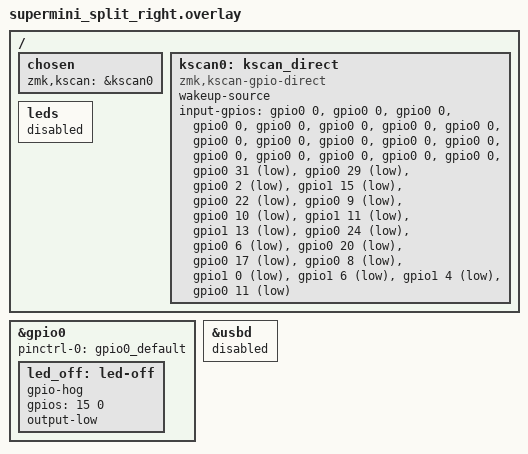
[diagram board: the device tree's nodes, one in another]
/*
 * Right half overlay — Super mini nrf52840
 *
 * This PCB is reversible: the right half is the same board flipped 180°.
 * The columns are therefore mirrored relative to the left overlay.
 * Each row's GPIO list runs innermost (toward centre) → outermost.
 *
 * Corrected column order (firmware pos → physical key → central pos):
 *   Key  0  P0.31  D21  (Y)    Key  5  P0.09  D1   (H)    Key 10  P0.06  D6   (N)
 *   Key  1  P0.29  D20  (U)    Key  6  P0.10  D10  (J)    Key 11  P0.20  D5   (M)
 *   Key  2  P0.02  D19  (I)    Key  7  P1.11  D16  (K)    Key 12  P0.17  D4   (,)
 *   Key  3  P1.15  D18  (O)    Key  8  P1.13  D14  (L)    Key 13  P0.08  D3   (.)
 *   Key  4  P0.22  D7   (P)    Key  9  P0.24  D15  (ö)    Key 14  P1.00  D2   (DEL)
 *   Key 15  P1.06  D0   (right thumb inner / RET)
 *   Key 16  P1.04  D8   (right thumb mid / SPACE)
 *   Key 17  P0.11  D9   (right thumb outer / BSPC)
 *
 * Positions 0–17 on the peripheral are transmitted to the central
 * and mapped to keymap positions 18–35 (central offset = 18).
 */

&gpio0 {
    /* Wir setzen den Pin der blauen LED (meist Pin 15 beim nRF52840) auf Input, 
       damit er nicht mehr angesteuert wird. */
    pinctrl-0 = <&gpio0_default>;
};

/ {
    chosen {
        zmk,kscan = &kscan0;
    };

    kscan0: kscan_direct {
        compatible = "zmk,kscan-gpio-direct";
        wakeup-source;
        input-gpios
            /* top row — innermost (Y) → outermost (P) */
            = <&gpio0 0 0>, <&gpio0 0 0>, <&gpio0 0 0>, <&gpio0 0 0>, <&gpio0 0 0>, 
            <&gpio0 0 0>, <&gpio0 0 0>, <&gpio0 0 0>, <&gpio0 0 0>, <&gpio0 0 0>, 
            <&gpio0 0 0>, <&gpio0 0 0>, <&gpio0 0 0>, <&gpio0 0 0>, <&gpio0 0 0>, 
            <&gpio0 0 0>, <&gpio0 0 0>, <&gpio0 0 0>

            , <&gpio0 31 (GPIO_ACTIVE_LOW | GPIO_PULL_UP)>   /* key  0  P0.31  Y */
            , <&gpio0 29 (GPIO_ACTIVE_LOW | GPIO_PULL_UP)>   /* key  1  P0.29  U */
            , <&gpio0  2 (GPIO_ACTIVE_LOW | GPIO_PULL_UP)>   /* key  2  P0.02  I */
            , <&gpio1 15 (GPIO_ACTIVE_LOW | GPIO_PULL_UP)>   /* key  3  P1.15  O */
            , <&gpio0 22 (GPIO_ACTIVE_LOW | GPIO_PULL_UP)>   /* key  4  P0.22  P */
            /* mid row — innermost (H) → outermost (ö) */
            , <&gpio0  9 (GPIO_ACTIVE_LOW | GPIO_PULL_UP)>   /* key  5  P0.09  H */
            , <&gpio0 10 (GPIO_ACTIVE_LOW | GPIO_PULL_UP)>   /* key  6  P0.10  J */
            , <&gpio1 11 (GPIO_ACTIVE_LOW | GPIO_PULL_UP)>   /* key  7  P1.11  K */
            , <&gpio1 13 (GPIO_ACTIVE_LOW | GPIO_PULL_UP)>   /* key  8  P1.13  L */
            , <&gpio0 24 (GPIO_ACTIVE_LOW | GPIO_PULL_UP)>   /* key  9  P0.24  ö */
            /* bot row — innermost (N) → outermost (DEL) */
            , <&gpio0  6 (GPIO_ACTIVE_LOW | GPIO_PULL_UP)>   /* key 10  P0.06  N */
            , <&gpio0 20 (GPIO_ACTIVE_LOW | GPIO_PULL_UP)>   /* key 11  P0.20  M */
            , <&gpio0 17 (GPIO_ACTIVE_LOW | GPIO_PULL_UP)>   /* key 12  P0.17  , */
            , <&gpio0  8 (GPIO_ACTIVE_LOW | GPIO_PULL_UP)>   /* key 13  P0.08  . */
            , <&gpio1  0 (GPIO_ACTIVE_LOW | GPIO_PULL_UP)>   /* key 14  P1.00  DEL */
            /* thumbs */
            , <&gpio1  6 (GPIO_ACTIVE_LOW | GPIO_PULL_UP)>   /* key 15  P0.11  thumb inner (RET) */
            , <&gpio1  4 (GPIO_ACTIVE_LOW | GPIO_PULL_UP)>   /* key 16  P1.04  thumb mid (SPACE) */
            , <&gpio0 11 (GPIO_ACTIVE_LOW | GPIO_PULL_UP)>   /* key 17  P1.06  thumb outer (BSPC) */
            ;
    };

    /*
     * Disable the onboard blue LED (P0.15) so no subsystem can blink it.
     * The gpio-hog keeps the pin driven low (LED off) from early GPIO init.
     */
    leds { status = "disabled"; };
};

&gpio0 {
    led_off: led-off {
        gpio-hog;
        gpios = <15 0>;
        output-low;
    };
};

/* The right peripheral does not use USB — disabling usbd prevents the USB
 * device controller from starting, which eliminates USB-state-dependent
 * LED toggling and saves power. */
&usbd { status = "disabled"; };

